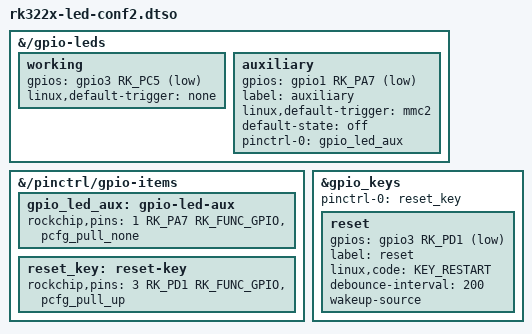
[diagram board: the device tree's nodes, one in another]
/dts-v1/;
/plugin/;

#include <dt-bindings/gpio/gpio.h>
#include <dt-bindings/input/input.h>
#include <dt-bindings/pinctrl/rockchip.h>

&{/gpio-leds} {
	working {
		gpios = <&gpio3 RK_PC5 GPIO_ACTIVE_LOW>;
		linux,default-trigger = "none";
	};

	auxiliary {
		gpios = <&gpio1 RK_PA7 GPIO_ACTIVE_LOW>;
		label = "auxiliary";
		linux,default-trigger = "mmc2";
		default-state = "off";
		pinctrl-names = "default";
		pinctrl-0 = <&gpio_led_aux>;
	};
};

&{/pinctrl/gpio-items} {
	gpio_led_aux: gpio-led-aux {
		rockchip,pins =  <1 RK_PA7 RK_FUNC_GPIO &pcfg_pull_none>;
	};

	reset_key: reset-key {
		rockchip,pins = <3 RK_PD1 RK_FUNC_GPIO &pcfg_pull_up>;
	};
};

&gpio_keys {
	pinctrl-names = "default";
	pinctrl-0 = <&reset_key>;

	reset {
		gpios = <&gpio3 RK_PD1 GPIO_ACTIVE_LOW>;
		label = "reset";
		linux,code = <KEY_RESTART>;
		debounce-interval = <200>;
		wakeup-source;
	};
};
